# XMC4700 register map
Vendor: Infineon; File version: 1.3.0 (Reference Manual v1.3)
CPU: CM4 r2p0, little endian, MPU, FPU, 6 interrupt priority bits
Registers are 32-bit, read-write, reset 0x0 unless marked. A register's access mark holds for its fields unless they carry their own. Offsets are from the block's base; [hi:lo] are bit positions; {n}, {i} and the like mark numbered series; 'fields as' and 'values as' point back to an identical list.

## CCU80_CC80 — Capture Compare Unit 8 - Unit 0
Base 0x40020100
Same registers: CCU80_CC81 0x40020200, CCU80_CC82 0x40020300, CCU80_CC83 0x40020400, CCU81_CC80 0x40024100, CCU81_CC81 0x40024200, CCU81_CC82 0x40024300, CCU81_CC83 0x40024400
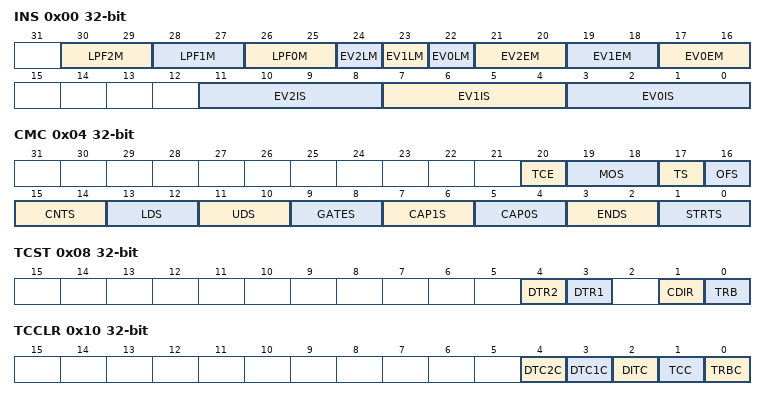
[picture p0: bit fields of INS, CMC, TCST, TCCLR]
0x00 INS — Input Selector Configuration
  [30:29] LPF2M — Event 2 Low Pass Filter Configuration
    0=LPF is disabled; 1=3 clock cycles of fCCU8; 2=5 clock cycles of fCCU8; 3=7 clock cycles of fCCU8
  [28:27] LPF1M — Event 1 Low Pass Filter Configuration
    values as LPF2M
  [26:25] LPF0M — Event 0 Low Pass Filter Configuration
    values as LPF2M
  [24] EV2LM — Event 2 Level Selection
    0=Active on HIGH level; 1=Active on LOW level
  [23] EV1LM — Event 1 Level Selection
    0=Active on HIGH level; 1=Active on LOW level
  [22] EV0LM — Event 0 Level Selection
    0=Active on HIGH level; 1=Active on LOW level
  [21:20] EV2EM — Event 2 Edge Selection
    0=No action; 1=Signal active on rising edge; 2=Signal active on falling edge; 3=Signal active on both edges
  [19:18] EV1EM — Event 1 Edge Selection
    values as EV2EM
  [17:16] EV0EM — Event 0 Edge Selection
    values as EV2EM
  [11:8] EV2IS — Event 2 signal selection
    0=CCU8x.INyA; 1=CCU8x.INyB; 2=CCU8x.INyC; 3=CCU8x.INyD; 4=CCU8x.INyE; 5=CCU8x.INyF; 6=CCU8x.INyG; 7=CCU8x.INyH; 8=CCU8x.INyI; 9=CCU8x.INyJ; 10=CCU8x.INyK; 11=CCU8x.INyL; 12=CCU8x.INyM; 13=CCU8x.INyN; 14=CCU8x.INyO; 15=CCU8x.INyP
  [7:4] EV1IS — Event 1 signal selection
    values as EV2IS
  [3:0] EV0IS — Event 0 signal selection
    values as EV2IS
0x04 CMC — Connection Matrix Control
  [20] TCE — Timer Concatenation Enable
    0=Timer concatenation is disabled; 1=Timer concatenation is enabled
  [19:18] MOS — External Modulation Functionality Selector
  [17] TS — Trap Function Selector
    0=Trap function disabled; 1=TRAP function connected to Event 2
  [16] OFS — Override Function Selector
    0=Override functionality disabled; 1=Status bit trigger override connected to Event 1; Status bit value override connected to Event 2
  [15:14] CNTS — External Count Selector
    0=External Count Function deactivated; 1=External Count Function triggered by Event 0; 2=External Count Function triggered by Event 1; 3=External Count Function triggered by Event 2
  [13:12] LDS — External Timer Load Functionality Selector
  [11:10] UDS — External Up/Down Functionality Selector
    0=External Up/Down Function deactivated; 1=External Up/Down Function triggered by Event 0; 2=External Up/Down Function triggered by Event 1; 3=External Up/Down Function triggered by Event 2
  [9:8] GATES — External Gate Functionality Selector
    0=External Gating Function deactivated; 1=External Gating Function triggered by Event 0; 2=External Gating Function triggered by Event 1; 3=External Gating Function triggered by Event 2
  [7:6] CAP1S — External Capture 1 Functionality Selector
    0=External Capture 1 Function deactivated; 1=External Capture 1 Function triggered by Event 0; 2=External Capture 1 Function triggered by Event 1; 3=External Capture 1 Function triggered by Event 2
  [5:4] CAP0S — External Capture 0 Functionality Selector
    0=External Capture 0 Function deactivated; 1=External Capture 0 Function triggered by Event 0; 2=External Capture 0 Function triggered by Event 1; 3=External Capture 0 Function triggered by Event 2
  [3:2] ENDS — External Stop Functionality Selector
    0=External Stop Function deactivated; 1=External Stop Function triggered by Event 0; 2=External Stop Function triggered by Event 1; 3=External Stop Function triggered by Event 2
  [1:0] STRTS — External Start Functionality Selector
    0=External Start Function deactivated; 1=External Start Function triggered by Event 0; 2=External Start Function triggered by Event 1; 3=External Start Function triggered by Event 2
0x08 TCST ro — Slice Timer Status
  [4] DTR2 — Dead Time Counter 2 Run bit
    0=Dead Time counter is idle; 1=Dead Time counter is running
  [3] DTR1 — Dead Time Counter 1 Run bit
    0=Dead Time counter is idle; 1=Dead Time counter is running
  [1] CDIR — Timer Counting Direction
    0=Timer is counting up; 1=Timer is counting down
  [0] TRB — Timer Run Bit
    0=Timer is stopped; 1=Timer is running
0x0C TCSET wo — Slice Timer Run Set
  [0] TRBS — Timer Run Bit set
0x10 TCCLR wo — Slice Timer Clear
  [4] DTC2C — Dead Time Counter 2 Clear
  [3] DTC1C — Dead Time Counter 1 Clear
  [2] DITC — Dither Counter Clear
  [1] TCC — Timer Clear
  [0] TRBC — Timer Run Bit Clear
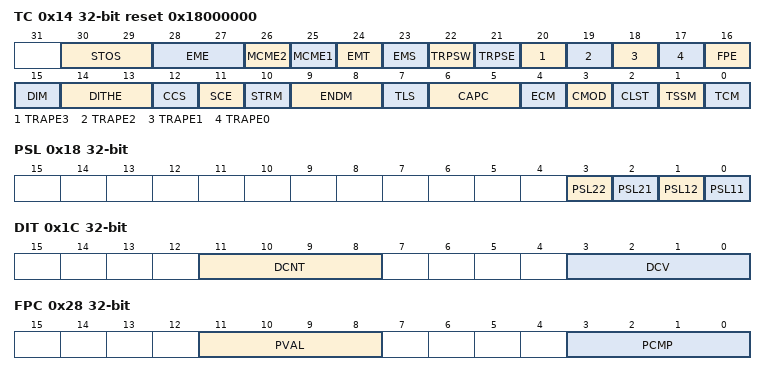
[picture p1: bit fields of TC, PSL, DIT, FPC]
0x14 TC access per field reset 0x18000000 — Slice Timer Control
  [30:29] STOS rw — Status bit output selector
    0=CC8yST1 forward to CCU8x.STy; 1=CC8yST2 forward to CCU8x.STy; 2=CC8yST1 AND CC8yST2 forward to CCU8x.STy; 3=CC8yST1 OR CC8yST2 forward to CCU8x.STy
  [28:27] EME rw — External Modulation Channel enable
    0=External Modulation functionality doesn't affect any channel; 1=External Modulation only applied on channel 1; 2=External Modulation only applied on channel 2; 3=External Modulation applied on both channels
  [26] MCME2 rw — Multi Channel Mode Enable for Channel 2
    0=Multi Channel Mode in Channel 2 is disabled; 1=Multi Channel Mode in Channel 2 is enabled
  [25] MCME1 rw — Multi Channel Mode Enable for Channel 1
    0=Multi Channel Mode in Channel 1 is disabled; 1=Multi Channel Mode in Channel 1 is enabled
  [24] EMT rw — External Modulation Type
    0=External Modulation functionality is clearing the CC8ySTx bits; 1=External Modulation functionality is gating the outputs
  [23] EMS rw — External Modulation Synchronization
    0=External Modulation functionality is not synchronized with the PWM signal; 1=External Modulation functionality is synchronized with the PWM signal
  [22] TRPSW rw — TRAP State Clear Control
    0=The slice exits the TRAP state automatically when the TRAP condition is not present (Trap state cleared by HW and SW); 1=The TRAP state can only be exited by a SW request
  [21] TRPSE rw — TRAP Synchronization Enable
    0=Exiting from TRAP state isn't synchronized with the PWM signal; 1=Exiting from TRAP state is synchronized with the PWM signal
  [20] TRAPE3 rw — TRAP enable for CCU8x.OUTy3
  [19] TRAPE2 rw — TRAP enable for CCU8x.OUTy2
  [18] TRAPE1 rw — TRAP enable for CCU8x.OUTy1
  [17] TRAPE0 rw — TRAP enable for CCU8x.OUTy0
    0=TRAP functionality has no effect on the CCU8x.OUTy0 output; 1=TRAP functionality affects the CCU8x.OUTy0 output
  [16] FPE rw — Floating Prescaler enable
    0=Floating prescaler mode is disabled; 1=Floating prescaler mode is enabled
  [15] DIM rw — Dither input selector
    0=Slice is using it own dither unit; 1=Slice is connected to the dither unit of slice 0
  [14:13] DITHE rw — Dither Enable
    0=Dither is disabled; 1=Dither is applied to the Period; 2=Dither is applied to the Compare; 3=Dither is applied to the Period and Compare
  [12] CCS rw — Continuous Capture Enable
    0=The capture into a specific capture register is done with the rules linked with the full flags, described at ; 1=The capture into the capture registers is always done regardless of the full flag status (even if the register has not been read back)
  [11] SCE rw — Equal Capture Event enable
    0=Capture into CC8yC0VThis register contains the values associated with the Capture 0 field./CC8yC1VThis register contains the values associated with the Capture 1 field. registers control by CCycapt0 and capture into CC8yC3VThis register contains the values associated with the Capture 3 field./CC8yC2VThis register contains the values associated with the Capture 2 field. control by CCycapt1; 1=Capture into CC8yC0VThis register contains the values associated with the Capture 0 field./CC8yC1VThis register contains the values associated with the Capture 1 field. and CC8yC3VThis register contains the values associated with the Capture 3 field./CC8yC2VThis register contains the values associated with the Capture 2 field. control by CCycapt1
  [10] STRM rw — Extended Start Function Control
    0=Sets run bit only (default start); 1=Clears the timer and sets run bit, if not set (flush/start)
  [9:8] ENDM rw — Extended Stop Function Control
    0=Clears the timer run bit only (default stop); 1=Clears the timer only (flush); 2=Clears the timer and run bit (flush/stop)
  [7] TLS rw — Timer Load selector
    0=Timer is loaded with the value of CR1; 1=Timer is loaded with the value of CR2
  [6:5] CAPC rw — Clear on Capture Control
    0=Timer is never cleared on a capture event; 1=Timer is cleared on a capture event into capture registers 2 and 3. (When SCE = 1#, Timer is always cleared in a capture event); 2=Timer is cleared on a capture event into capture registers 0 and 1. (When SCE = 1#, Timer is always cleared in a capture event); 3=Timer is always cleared in a capture event
  [4] ECM rw — Extended Capture Mode
    0=Normal Capture Mode. Clear of the Full Flag of each capture register is done by accessing the registers individually only.; 1=Extended Capture Mode. Clear of the Full Flag of each capture register is done not only by accessing the individual registers but also by accessing the ECRD register. When reading the ECRD register, only the capture register register full flag pointed by the VPTR is cleared
  [3] CMOD ro — Capture Compare Mode
    0=Compare Mode; 1=Capture Mode
  [2] CLST rw — Shadow Transfer on Clear
  [1] TSSM rw — Timer Single Shot Mode
    0=Single shot mode is disabled; 1=Single shot mode is enabled
  [0] TCM rw — Timer Counting Mode
    0=Edge aligned mode; 1=Center aligned mode
0x18 PSL — Passive Level Config
  [all] fields
    0=Passive Level is LOW; 1=Passive Level is HIGH
  [3] PSL22 — Output Passive Level for CCU8x.OUTy3
  [2] PSL21 — Output Passive Level for CCU8x.OUTy2
  [1] PSL12 — Output Passive Level for CCU8x.OUTy1
  [0] PSL11 — Output Passive Level for CCU8x.OUTy0
0x1C DIT ro — Dither Config
  [11:8] DCNT — Dither counter actual value
  [3:0] DCV — Dither compare Value
0x20 DITS — Dither Shadow Register
  [3:0] DCVS — Dither Shadow Compare Value
0x24 PSC — Prescaler Control
  [3:0] PSIV — Prescaler Initial Value
0x28 FPC access per field — Floating Prescaler Control
  [11:8] PVAL rw — Actual Prescaler Value
  [3:0] PCMP ro — Floating Prescaler Compare Value
0x2C FPCS — Floating Prescaler Shadow
  [3:0] PCMP — Floating Prescaler Shadow Compare Value
0x30 PR ro — Timer Period Value
  [15:0] PR — Period Register
0x34 PRS — Timer Shadow Period Value
  [15:0] PRS — Period Register
0x38 CR1 ro — Channel 1 Compare Value
  [15:0] CR1 — Compare Register for Channel 1
0x3C CR1S — Channel 1 Compare Shadow Value
  [15:0] CR1S — Shadow Compare Register for Channel 1
0x40 CR2 ro — Channel 2 Compare Value
  [15:0] CR2 — Compare Register for Channel 2
0x44 CR2S — Channel 2 Compare Shadow Value
  [15:0] CR2S — Shadow Compare Register for Channel 2
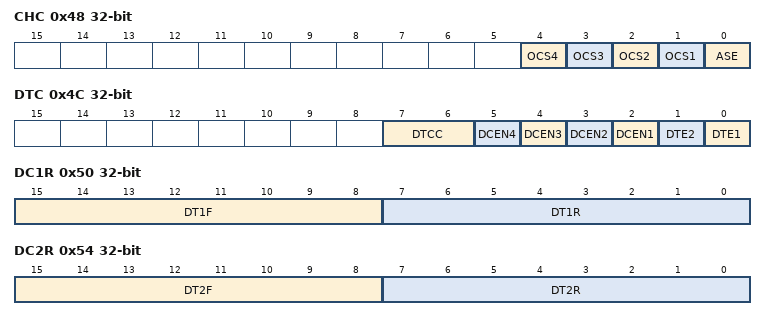
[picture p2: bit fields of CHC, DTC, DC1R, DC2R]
0x48 CHC — Channel Control
  [4] OCS4 — Output selector for CCU8x.OUTy3
    0=Inverted CC8yST2 signal path is connected to the CCU8x.OUTy3; 1=CC8yST2 signal path is connected to the CCU8x.OUTy3
  [3] OCS3 — Output selector for CCU8x.OUTy2
    0=CC8yST2 signal path is connected to the CCU8x.OUTy2; 1=Inverted CCST2 signal path is connected to the CCU8x.OUTy2
  [2] OCS2 — Output selector for CCU8x.OUTy1
    0=Inverted CC8yST1 signal path is connected to the CCU8x.OUTy1; 1=CC8yST1 signal path is connected to the CCU8x.OUTy1
  [1] OCS1 — Output selector for CCU8x.OUTy0
    0=CC8yST1 signal path is connected to the CCU8x.OUTy0; 1=Inverted CC8yST1 signal path is connected to the CCU8x.OUTy0
  [0] ASE — Asymmetric PWM mode Enable
    0=Asymmetric PWM is disabled; 1=Asymmetric PWM is enabled
0x4C DTC — Dead Time Control
  [7:6] DTCC — Dead Time clock control
    0=ftclk; 1=ftclk/2; 2=ftclk/4; 3=ftclk/8
  [5] DCEN4 — Dead Time Enable for inverted CC8yST2
    0=Dead Time for inverted CC8yST2 path is disabled; 1=Dead Time for inverted CC8yST2 path is enabled
  [4] DCEN3 — Dead Time Enable for CC8yST2
    0=Dead Time for CC8yST2 path is disabled; 1=Dead Time for CC8yST2 path is enabled
  [3] DCEN2 — Dead Time Enable for inverted CC8yST1
    0=Dead Time for inverted CC8yST1 path is disabled; 1=Dead Time for inverted CC8yST1 path is enabled
  [2] DCEN1 — Dead Time Enable for CC8yST1
    0=Dead Time for CC8yST1 path is disabled; 1=Dead Time for CC8yST1 path is enabled
  [1] DTE2 — Dead Time Enable for Channel 2
    0=Dead Time for channel 2 is disabled; 1=Dead Time for channel 2 is enabled
  [0] DTE1 — Dead Time Enable for Channel 1
    0=Dead Time for channel 1 is disabled; 1=Dead Time for channel 1 is enabled
0x50 DC1R — Channel 1 Dead Time Values
  [15:8] DT1F — Fall Value for Dead Time of Channel 1
  [7:0] DT1R — Rise Value for Dead Time of Channel 1
0x54 DC2R — Channel 2 Dead Time Values
  [15:8] DT2F — Fall Value for Dead Time of Channel 2
  [7:0] DT2R — Rise Value for Dead Time of Channel 2
0x70 TIMER — Timer Value
  [15:0] TVAL
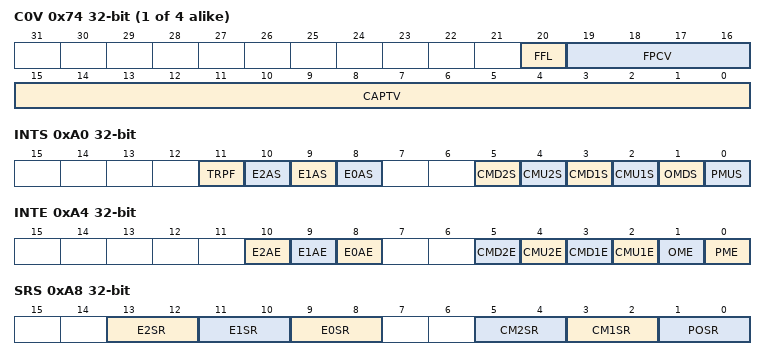
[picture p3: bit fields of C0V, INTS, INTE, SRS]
{0x74+4i} C{i}V ro read-has-side-effects (i=0..3) — Capture Register {i}
  [20] FFL — Full Flag
    0=No new value was captured into the specific capture register; 1=A new value was captured into the specific register
  [19:16] FPCV — Prescaler Value
  [15:0] CAPTV — Capture Value
0xA0 INTS ro — Interrupt Status
  [11] TRPF — Trap Flag Status
  [10] E2AS — Event 2 Detection Status
    0=Event 2 not detected; 1=Event 2 detected
  [9] E1AS — Event 1 Detection Status
    0=Event 1 not detected; 1=Event 1 detected
  [8] E0AS — Event 0 Detection Status
    0=Event 0 not detected; 1=Event 0 detected
  [5] CMD2S — Channel 2 Compare Match while Counting Down
    0=Compare match while counting down not detected; 1=Compare match while counting down detected
  [4] CMU2S — Channel 2 Compare Match while Counting Up
    0=Compare match while counting up not detected; 1=Compare match while counting up detected
  [3] CMD1S — Channel 1 Compare Match while Counting Down
    values as CMD2S
  [2] CMU1S — Channel 1 Compare Match while Counting Up
    values as CMU2S
  [1] OMDS — One Match while Counting Down
    0=One match while counting down not detected; 1=One match while counting down detected
  [0] PMUS — Period Match while Counting Up
    0=Period match while counting up not detected; 1=Period match while counting up detected
0xA4 INTE — Interrupt Enable Control
  [10] E2AE — Event 2 interrupt enable
    0=Event 2 detection interrupt is disabled; 1=Event 2 detection interrupt is enabled
  [9] E1AE — Event 1 interrupt enable
    0=Event 1 detection interrupt is disabled; 1=Event 1 detection interrupt is enabled
  [8] E0AE — Event 0 interrupt enable
    0=Event 0 detection interrupt is disabled; 1=Event 0 detection interrupt is enabled
  [5] CMD2E — Channel 2 Compare match while counting down enable
    0=Compare Match while counting down interrupt is disabled; 1=Compare Match while counting down interrupt is enabled
  [4] CMU2E — Channel 2 Compare match while counting up enable
    0=Compare Match while counting up interrupt is disabled; 1=Compare Match while counting up interrupt is enabled
  [3] CMD1E — Channel 1 Compare match while counting down enable
    values as CMD2E
  [2] CMU1E — Channel 1 Compare match while counting up enable
    values as CMU2E
  [1] OME — One match while counting down enable
    0=One Match interrupt is disabled; 1=One Match interrupt is enabled
  [0] PME — Period match while counting up enable
    0=Period Match interrupt is disabled; 1=Period Match interrupt is enabled
0xA8 SRS — Service Request Selector
  [13:12] E2SR — Event 2 Service request selector
    0=Forward to CC8ySR0; 1=Forward to CCvySR1; 2=Forward to CC8ySR2; 3=Forward to CC8ySR3
  [11:10] E1SR — Event 1 Service request selector
    {v}=Forward to CC8ySR{v} (v=0..3)
  [9:8] E0SR — Event 0 Service request selector
    0=Forward to CCvySR0; 1=Forward to CC8ySR1; 2=Forward to CC8ySR2; 3=Forward to CC8ySR3
  [5:4] CM2SR — Channel 2 Compare match Service request selector
    {v}=Forward to CC8ySR{v} (v=0..3)
  [3:2] CM1SR — Channel 1 Compare match Service request selector
    {v}=Forward to CC8ySR{v} (v=0..3)
  [1:0] POSR — Period/One match Service request selector
    {v}=Forward to CC8ySR{v} (v=0..3)
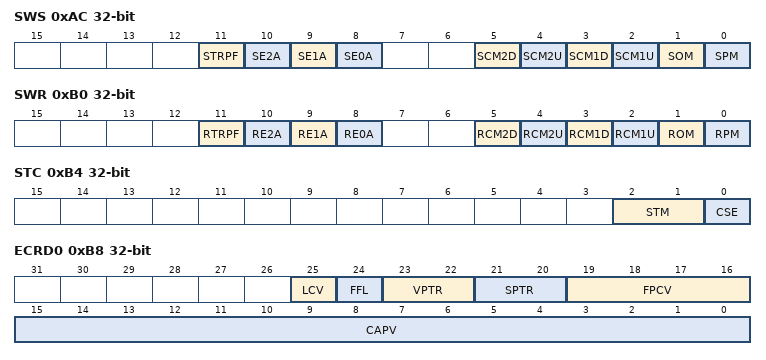
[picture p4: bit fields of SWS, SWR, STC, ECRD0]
0xAC SWS wo — Interrupt Status Set
  [11] STRPF — Trap Flag status set
  [10] SE2A — Event 2 detection set
  [9] SE1A — Event 1 detection set
  [8] SE0A — Event 0 detection set
  [5] SCM2D — Compare match while counting down set
  [4] SCM2U — Compare match while counting up set
  [3] SCM1D — Channel 1 Compare match while counting down set
  [2] SCM1U — Channel 1 Compare match while counting up set
  [1] SOM — One match while counting down set
  [0] SPM — Period match while counting up set
0xB0 SWR wo — Interrupt Status Clear
  [11] RTRPF — Trap Flag status clear
  [10] RE2A — Event 2 detection clear
  [9] RE1A — Event 1 detection clear
  [8] RE0A — Event 0 detection clear
  [5] RCM2D — Channel 2 Compare match while counting down clear
  [4] RCM2U — Channel 2 Compare match while counting up clear
  [3] RCM1D — Channel 1 Compare match while counting down clear
  [2] RCM1U — Channel 1 Compare match while counting up clear
  [1] ROM — One match while counting down clear
  [0] RPM — Period match while counting up clear
0xB4 STC — Shadow transfer control
  [2:1] STM — Shadow transfer mode
    0=Shadow transfer is done in Period Match and One match; 1=Shadow transfer is done only in Period Match; 2=Shadow transfer is done only in One Match
  [0] CSE — Cascaded shadow transfer enable
    0=Cascaded shadow transfer disabled; 1=Cascaded shadow transfer enabled
0xB8 ECRD0 ro read-has-side-effects — Extended Read Back 0
  [25] LCV — Lost Capture Value
    0=No capture was lost; 1=A capture was lost
  [24] FFL — Full Flag
    0=No new value was captured into this register; 1=A new value has been captured into this register
  [23:22] VPTR — Capture register pointer
    {v}=Capture register {v} (v=0..3)
  [21:20] SPTR — Slice pointer
    {v}=CC{v+80} (v=0..3)
  [19:16] FPCV — Prescaler Capture value
  [15:0] CAPV — Timer Capture Value
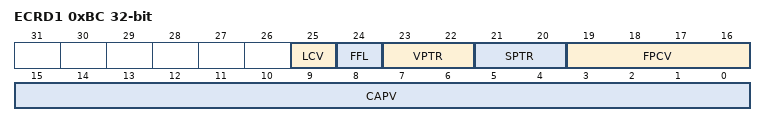
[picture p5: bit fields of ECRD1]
0xBC ECRD1 ro read-has-side-effects — Extended Read Back 1
  fields as ECRD0
